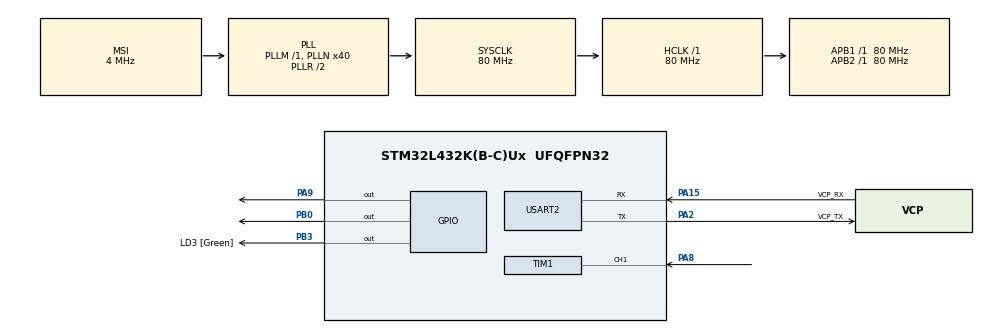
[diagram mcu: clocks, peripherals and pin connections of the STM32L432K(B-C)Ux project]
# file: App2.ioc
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Mcu.Family=STM32L4
Mcu.Name=STM32L432K(B-C)Ux
Mcu.Package=UFQFPN32
NVIC.PriorityGroup=NVIC_PRIORITYGROUP_4
NVIC.TIM1_CC_IRQn=true\:0\:0\:false\:false\:true\:true\:true
PA0.GPIO_Label=MCO [High speed clock in]
PA0.Signal=RCC_CK_IN
PA13\ (JTMS-SWDIO).GPIO_Label=SWDIO
PA13\ (JTMS-SWDIO).Mode=Serial_Wire
PA13\ (JTMS-SWDIO).Signal=SYS_JTMS-SWDIO
PA14\ (JTCK-SWCLK).GPIO_Label=SWCLK
PA14\ (JTCK-SWCLK).Mode=Serial_Wire
PA14\ (JTCK-SWCLK).Signal=SYS_JTCK-SWCLK
PA15\ (JTDI).GPIO_Label=VCP_RX
PA15\ (JTDI).Mode=Asynchronous
PA15\ (JTDI).Signal=USART2_RX
PA2.GPIO_Label=VCP_TX
PA2.Mode=Asynchronous
PA2.Signal=USART2_TX
PA8.Signal=S_TIM1_CH1
PA9.Signal=GPIO_Output
PB0.Signal=GPIO_Output
PB3\ (JTDO-TRACESWO).GPIO_Label=LD3 [Green]
PB3\ (JTDO-TRACESWO).Signal=GPIO_Output
PC14-OSC32_IN\ (PC14).Mode=LSE-External-Oscillator
PC14-OSC32_IN\ (PC14).Signal=RCC_OSC32_IN
PC15-OSC32_OUT\ (PC15).Mode=LSE-External-Oscillator
PC15-OSC32_OUT\ (PC15).Signal=RCC_OSC32_OUT
ProjectManager.HeapSize=0x200
ProjectManager.StackSize=0x400
ProjectManager.TargetToolchain=MDK-ARM V5
RCC.ADCFreq_Value=16000000
RCC.AHBFreq_Value=80000000
RCC.APB1Freq_Value=80000000
RCC.APB1TimFreq_Value=80000000
RCC.APB2Freq_Value=80000000
RCC.APB2TimFreq_Value=80000000
RCC.CortexFreq_Value=80000000
RCC.HCLKFreq_Value=80000000
RCC.HSE_VALUE=8000000
RCC.HSI16_VALUE=16000000
RCC.HSI48_VALUE=48000000
RCC.HSI_VALUE=16000000
RCC.MSI_VALUE=4000000
RCC.PLLMUL=RCC_PLLMUL_4
RCC.PLLN=40
RCC.SYSCLKFreq_VALUE=80000000
RCC.SYSCLKSource=RCC_SYSCLKSOURCE_PLLCLK
RCC.USBFreq_Value=16000000
RCC.VCOOutputFreq_Value=160000000
SH.S_TIM1_CH1.0=TIM1_CH1,Input_Capture1_from_TI1
TIM1.Channel-Input_Capture1_from_TI1=TIM_CHANNEL_1
TIM1.Period=0xffff-1
TIM1.Prescaler=80-1
USART2.VirtualMode-Asynchronous=VM_ASYNC
board=NUCLEO-L432KC

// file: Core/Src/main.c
/* USER CODE BEGIN Header */
/**
  ******************************************************************************
  * @file           : main.c
  * @brief          : Main program body
  ******************************************************************************
  * @attention
  *
  * <h2><center>&copy; Copyright (c) 2021 STMicroelectronics.
  * All rights reserved.</center></h2>
  *
  * This software component is licensed by ST under BSD 3-Clause license,
  * the "License"; You may not use this file except in compliance with the
  * License. You may obtain a copy of the License at:
  *                        opensource.org/licenses/BSD-3-Clause
  *
  ******************************************************************************
  */
/* USER CODE END Header */
#include "main.h"

/* USER CODE BEGIN Includes */
#include <stdio.h>
#include <string.h>
#include <stdlib.h>
#include "CoScheduler.h"
/* USER CODE END Includes */

TIM_HandleTypeDef htim1;

UART_HandleTypeDef huart2;

void SystemClock_Config(void);
static void MX_GPIO_Init(void);
static void MX_TIM1_Init(void);
static void MX_USART2_UART_Init(void);
void sendToBuzz(void);

/* USER CODE BEGIN 0 */
void delay (uint16_t time)
{
	__HAL_TIM_SET_COUNTER(&htim1, 0);
	while (__HAL_TIM_GET_COUNTER (&htim1) < time);
}

uint32_t Val1 = 0;
uint32_t Val2 = 0;
uint32_t Difference = 0;
uint8_t first_flag = 0;  /*flag to indicate if the first value is captured*/
uint8_t Distance  = 0;

#define TRIG_PIN GPIO_PIN_9
#define TRIG_PORT GPIOA

/*the callback function*/

void HAL_TIM_IC_CaptureCallback(TIM_HandleTypeDef *htim)
{
	if (htim->Channel == HAL_TIM_ACTIVE_CHANNEL_1)  /* if interrupt source is channel 1 "the one we configured" */
	{
		if (first_flag==0) /* if the first value is not captured, read it */
		{
			Val1 = HAL_TIM_ReadCapturedValue(htim, TIM_CHANNEL_1); /* read the first value */
			first_flag = 1;  /* set the first captured flag true */
			__HAL_TIM_SET_CAPTUREPOLARITY(htim, TIM_CHANNEL_1, TIM_INPUTCHANNELPOLARITY_FALLING);		/*change the polarity to falling edge*/
		}

		else if (first_flag==1)   // if the first is already read/captured
		{
			Val2 = HAL_TIM_ReadCapturedValue(htim, TIM_CHANNEL_1);  // read second value
			__HAL_TIM_SET_COUNTER(htim, 0);  // reset the counter

			if (Val2 > Val1)
			{
				Difference = Val2-Val1;
			}

			else if (Val1 > Val2)
			{
				Difference = (0xffff - Val1) + Val2; /*the time difference */
			}

			Distance = Difference*0.034/2;
			first_flag = 0; // set it back to false

			/* set polarity to be rising edge */
			__HAL_TIM_SET_CAPTUREPOLARITY(htim, TIM_CHANNEL_1, TIM_INPUTCHANNELPOLARITY_RISING);
			__HAL_TIM_DISABLE_IT(&htim1, TIM_IT_CC1);
		}
	}
}

void readData (void)
{
	HAL_GPIO_WritePin(TRIG_PORT, TRIG_PIN, GPIO_PIN_RESET);  // pull the TRIG pin low
	delay(2);
	HAL_GPIO_WritePin(TRIG_PORT, TRIG_PIN, GPIO_PIN_SET);  // set the TRIG pin high
	delay(10);  // wait for 10 us
	HAL_GPIO_WritePin(TRIG_PORT, TRIG_PIN, GPIO_PIN_RESET);  // pull the TRIG pin low

	__HAL_TIM_ENABLE_IT(&htim1, TIM_IT_CC1);

	ReRunMe(2);
}

void sendToBuzz(void)
{

if(Distance<200){
		HAL_GPIO_WritePin(GPIOB, GPIO_PIN_0,GPIO_PIN_SET);
		HAL_Delay(Distance*9);
		HAL_GPIO_WritePin(GPIOB, GPIO_PIN_0,GPIO_PIN_RESET);
		HAL_Delay(Distance*9);
}

  ReRunMe(1);
}
/* USER CODE END 0 */

int main(void)
{
  /* USER CODE BEGIN 1 */
	Task A;
	A.priority = 3;
	A.func_ptr = readData;
	A.Task_name = "Task A";

	Task B;
	B.priority = 2;
	B.func_ptr = sendToBuzz;
	B.Task_name = "Task B";
  /* USER CODE END 1 */

  /* MCU Configuration--------------------------------------------------------*/

  /* Reset of all peripherals, Initializes the Flash interface and the Systick. */
  HAL_Init();

  /* Configure the system clock */
  SystemClock_Config();

  /* Initialize all configured peripherals */
  MX_GPIO_Init();
  MX_TIM1_Init();
  MX_USART2_UART_Init();
  /* USER CODE BEGIN 2 */
	HAL_TIM_IC_Start_IT(&htim1,TIM_CHANNEL_1);
	Init();
	QueTask(A);
	QueTask(B);
	//HAL_SYSTICK_Config(0x3D08CE);//79999*50
  /* USER CODE END 2 */

  /* Infinite loop */
  /* USER CODE BEGIN WHILE */
  while (1)
  {
		Dispatch();
    /* USER CODE END WHILE */
  }
}

void SystemClock_Config(void)
{
  RCC_OscInitTypeDef RCC_OscInitStruct = {0};
  RCC_ClkInitTypeDef RCC_ClkInitStruct = {0};
  RCC_PeriphCLKInitTypeDef PeriphClkInit = {0};

  /** Configure LSE Drive Capability
  */
  HAL_PWR_EnableBkUpAccess();
  __HAL_RCC_LSEDRIVE_CONFIG(RCC_LSEDRIVE_LOW);
  /** Initializes the RCC Oscillators according to the specified parameters
  * in the RCC_OscInitTypeDef structure.
  */
  RCC_OscInitStruct.OscillatorType = RCC_OSCILLATORTYPE_LSE|RCC_OSCILLATORTYPE_MSI;
  RCC_OscInitStruct.LSEState = RCC_LSE_ON;
  RCC_OscInitStruct.MSIState = RCC_MSI_ON;
  RCC_OscInitStruct.MSICalibrationValue = 0;
  RCC_OscInitStruct.MSIClockRange = RCC_MSIRANGE_6;
  RCC_OscInitStruct.PLL.PLLState = RCC_PLL_ON;
  RCC_OscInitStruct.PLL.PLLSource = RCC_PLLSOURCE_MSI;
  RCC_OscInitStruct.PLL.PLLM = 1;
  RCC_OscInitStruct.PLL.PLLN = 40;
  RCC_OscInitStruct.PLL.PLLP = RCC_PLLP_DIV7;
  RCC_OscInitStruct.PLL.PLLQ = RCC_PLLQ_DIV2;
  RCC_OscInitStruct.PLL.PLLR = RCC_PLLR_DIV2;
  if (HAL_RCC_OscConfig(&RCC_OscInitStruct) != HAL_OK)
  {
    Error_Handler();
  }
  /** Initializes the CPU, AHB and APB buses clocks
  */
  RCC_ClkInitStruct.ClockType = RCC_CLOCKTYPE_HCLK|RCC_CLOCKTYPE_SYSCLK
                              |RCC_CLOCKTYPE_PCLK1|RCC_CLOCKTYPE_PCLK2;
  RCC_ClkInitStruct.SYSCLKSource = RCC_SYSCLKSOURCE_PLLCLK;
  RCC_ClkInitStruct.AHBCLKDivider = RCC_SYSCLK_DIV1;
  RCC_ClkInitStruct.APB1CLKDivider = RCC_HCLK_DIV1;
  RCC_ClkInitStruct.APB2CLKDivider = RCC_HCLK_DIV1;

  if (HAL_RCC_ClockConfig(&RCC_ClkInitStruct, FLASH_LATENCY_4) != HAL_OK)
  {
    Error_Handler();
  }
  PeriphClkInit.PeriphClockSelection = RCC_PERIPHCLK_USART2;
  PeriphClkInit.Usart2ClockSelection = RCC_USART2CLKSOURCE_PCLK1;
  if (HAL_RCCEx_PeriphCLKConfig(&PeriphClkInit) != HAL_OK)
  {
    Error_Handler();
  }
  /** Configure the main internal regulator output voltage
  */
  if (HAL_PWREx_ControlVoltageScaling(PWR_REGULATOR_VOLTAGE_SCALE1) != HAL_OK)
  {
    Error_Handler();
  }
  /** Enable MSI Auto calibration
  */
  HAL_RCCEx_EnableMSIPLLMode();
}

static void MX_TIM1_Init(void)
{

  TIM_MasterConfigTypeDef sMasterConfig = {0};
  TIM_IC_InitTypeDef sConfigIC = {0};

  htim1.Instance = TIM1;
  htim1.Init.Prescaler = 80-1;
  htim1.Init.CounterMode = TIM_COUNTERMODE_UP;
  htim1.Init.Period = 0xffff-1;
  htim1.Init.ClockDivision = TIM_CLOCKDIVISION_DIV1;
  htim1.Init.RepetitionCounter = 0;
  htim1.Init.AutoReloadPreload = TIM_AUTORELOAD_PRELOAD_DISABLE;
  if (HAL_TIM_IC_Init(&htim1) != HAL_OK)
  {
    Error_Handler();
  }
  sMasterConfig.MasterOutputTrigger = TIM_TRGO_RESET;
  sMasterConfig.MasterOutputTrigger2 = TIM_TRGO2_RESET;
  sMasterConfig.MasterSlaveMode = TIM_MASTERSLAVEMODE_DISABLE;
  if (HAL_TIMEx_MasterConfigSynchronization(&htim1, &sMasterConfig) != HAL_OK)
  {
    Error_Handler();
  }
  sConfigIC.ICPolarity = TIM_INPUTCHANNELPOLARITY_RISING;
  sConfigIC.ICSelection = TIM_ICSELECTION_DIRECTTI;
  sConfigIC.ICPrescaler = TIM_ICPSC_DIV1;
  sConfigIC.ICFilter = 0;
  if (HAL_TIM_IC_ConfigChannel(&htim1, &sConfigIC, TIM_CHANNEL_1) != HAL_OK)
  {
    Error_Handler();
  }

}

static void MX_USART2_UART_Init(void)
{

  huart2.Instance = USART2;
  huart2.Init.BaudRate = 115200;
  huart2.Init.WordLength = UART_WORDLENGTH_8B;
  huart2.Init.StopBits = UART_STOPBITS_1;
  huart2.Init.Parity = UART_PARITY_NONE;
  huart2.Init.Mode = UART_MODE_TX_RX;
  huart2.Init.HwFlowCtl = UART_HWCONTROL_NONE;
  huart2.Init.OverSampling = UART_OVERSAMPLING_16;
  huart2.Init.OneBitSampling = UART_ONE_BIT_SAMPLE_DISABLE;
  huart2.AdvancedInit.AdvFeatureInit = UART_ADVFEATURE_NO_INIT;
  if (HAL_UART_Init(&huart2) != HAL_OK)
  {
    Error_Handler();
  }

}

static void MX_GPIO_Init(void)
{
  GPIO_InitTypeDef GPIO_InitStruct = {0};

  /* GPIO Ports Clock Enable */
  __HAL_RCC_GPIOC_CLK_ENABLE();
  __HAL_RCC_GPIOA_CLK_ENABLE();
  __HAL_RCC_GPIOB_CLK_ENABLE();

  /*Configure GPIO pin Output Level */
  HAL_GPIO_WritePin(GPIOB, GPIO_PIN_0|LD3_Pin, GPIO_PIN_RESET);

  /*Configure GPIO pin Output Level */
  HAL_GPIO_WritePin(GPIOA, GPIO_PIN_9, GPIO_PIN_RESET);

  /*Configure GPIO pins : PB0 LD3_Pin */
  GPIO_InitStruct.Pin = GPIO_PIN_0|LD3_Pin;
  GPIO_InitStruct.Mode = GPIO_MODE_OUTPUT_PP;
  GPIO_InitStruct.Pull = GPIO_NOPULL;
  GPIO_InitStruct.Speed = GPIO_SPEED_FREQ_LOW;
  HAL_GPIO_Init(GPIOB, &GPIO_InitStruct);

  /*Configure GPIO pin : PA9 */
  GPIO_InitStruct.Pin = GPIO_PIN_9;
  GPIO_InitStruct.Mode = GPIO_MODE_OUTPUT_PP;
  GPIO_InitStruct.Pull = GPIO_NOPULL;
  GPIO_InitStruct.Speed = GPIO_SPEED_FREQ_LOW;
  HAL_GPIO_Init(GPIOA, &GPIO_InitStruct);

  /*Configure GPIO pin : PA10 */
  GPIO_InitStruct.Pin = GPIO_PIN_10;
  GPIO_InitStruct.Mode = GPIO_MODE_INPUT;
  GPIO_InitStruct.Pull = GPIO_NOPULL;
  HAL_GPIO_Init(GPIOA, &GPIO_InitStruct);

}

void Error_Handler(void)
{
  __disable_irq();
  while (1)
  {
  }
}

/************************ (C) COPYRIGHT STMicroelectronics *****END OF FILE****/
